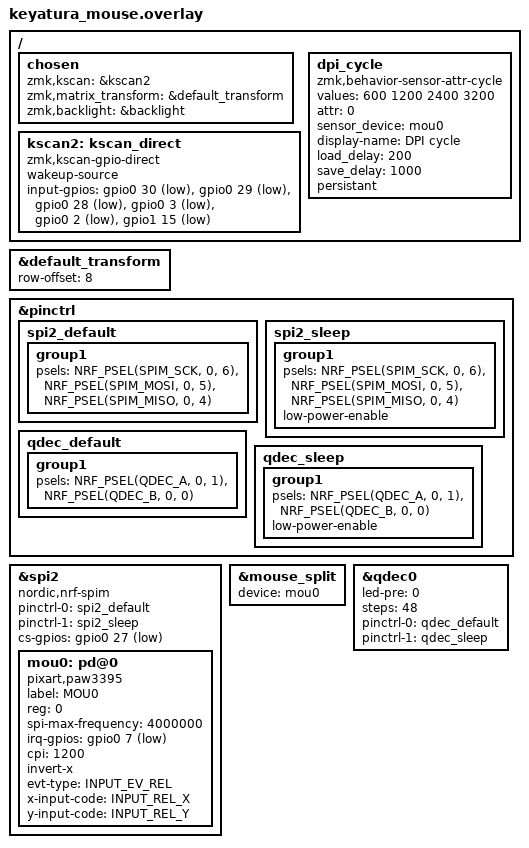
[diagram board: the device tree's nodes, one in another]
#include "keyatura.dtsi"
#include "keyatura_esb_addr.dtsi"
#include "mouse_leds.dtsi"

#define INPUT_EV_KEY 0x01               /**< Key event */
#define INPUT_EV_REL 0x02               /**< Relative coordinate event */
#define INPUT_EV_ABS 0x03               /**< Absolute coordinate event */
#define INPUT_EV_MSC 0x04               /**< Miscellaneous event */
#define INPUT_EV_VENDOR_START 0xf0      /**< Vendor specific event start */
#define INPUT_EV_VENDOR_STOP 0xff       /**< Vendor specific event stop */

#define INPUT_REL_X 0x00                /**< Relative X coordinate */
#define INPUT_REL_Y 0x01                /**< Relative Y coordinate */
#define INPUT_REL_WHEEL 0x08            /**< Relative wheel coordinate */
#define INPUT_REL_HWHEEL 0x06           /**< Relative horizontal wheel coordinate */
#define INPUT_REL_MISC 0x09             /**< Relative misc coordinate */

// &physical_layout0 {
//     kscan = <&kscan2>;
// };

/ {
	chosen {
		zmk,kscan = &kscan2;
		// zmk,physical-layout = &physical_layout0;
		zmk,matrix_transform = &default_transform;
		zmk,backlight = &backlight;
	};
	
	kscan2: kscan_direct {
		compatible = "zmk,kscan-gpio-direct";
		wakeup-source;
		input-gpios
		= <&gpio0 30 (GPIO_ACTIVE_LOW | GPIO_PULL_UP)>
		, <&gpio0 29 (GPIO_ACTIVE_LOW | GPIO_PULL_UP)>
		, <&gpio0 28 (GPIO_ACTIVE_LOW | GPIO_PULL_UP)>
		, <&gpio0 3 (GPIO_ACTIVE_LOW | GPIO_PULL_UP)>
		, <&gpio0 2 (GPIO_ACTIVE_LOW | GPIO_PULL_UP)>
		, <&gpio1 15 (GPIO_ACTIVE_LOW | GPIO_PULL_UP)>
		;
	};
};

&default_transform {
	row-offset = <8>;
};

&pinctrl {
	spi2_default: spi2_default {
		group1 {
			psels = <NRF_PSEL(SPIM_SCK, 0, 6)>,
			<NRF_PSEL(SPIM_MOSI, 0, 5)>,
			<NRF_PSEL(SPIM_MISO, 0, 4)>;
		};
	};
	spi2_sleep: spi2_sleep {
		group1 {
			psels = <NRF_PSEL(SPIM_SCK, 0, 6)>,
			<NRF_PSEL(SPIM_MOSI, 0, 5)>,
			<NRF_PSEL(SPIM_MISO, 0, 4)>;
			low-power-enable;
		};
	};
};

#include <zephyr/dt-bindings/input/input-event-codes.h>

&spi2 {
	compatible = "nordic,nrf-spim";
	status = "okay";
	pinctrl-0 = <&spi2_default>;
	pinctrl-1 = <&spi2_sleep>;
	pinctrl-names = "default", "sleep";
	cs-gpios = <&gpio0 27 GPIO_ACTIVE_LOW>;
	
	mou0: pd@0 {
		compatible = "pixart,paw3395";
		status = "okay";
		label = "MOU0";
		reg = <0>;
		spi-max-frequency = <4000000>;
		
		// paw3395 driver parameters
		irq-gpios = <&gpio0 7 (GPIO_ACTIVE_LOW | GPIO_PULL_UP)>;
		cpi = <1200>;
		// swap-xy; /* optional */
		invert-x; /* optional */
		// invert-y; /* optional */
		evt-type = <INPUT_EV_REL>;
		x-input-code = <INPUT_REL_X>;
		y-input-code = <INPUT_REL_Y>;
	};
};

&mouse_split {
	device = <&mou0>;
};

/ {
	/delete-node/ m_encoder;
};

&pinctrl {
	qdec_default: qdec_default {
		group1 {
			psels = <NRF_PSEL(QDEC_A, 0, 1)>,
			<NRF_PSEL(QDEC_B, 0, 0)>;
			// bias-pull-up;
		};
	};
	
	
	// need second set of pins defined if deep sleep is enabled
	qdec_sleep: qdec_sleep {
		group1 {
			psels = <NRF_PSEL(QDEC_A, 0, 1)>,
			<NRF_PSEL(QDEC_B, 0, 0)>;
			// bias-pull-up; // TODO: find out if this makes sense with low-power-enable
			low-power-enable;
		};
	};
};

// Set up the QDEC hardware based driver and give it the same label as the deleted node.
m_encoder: &qdec0 {
	status = "okay";
	led-pre = <0>;
	steps = <48>;
	pinctrl-0 = <&qdec_default>;
	pinctrl-1 = <&qdec_sleep>;
	pinctrl-names = "default", "sleep";
};

/ {
	dpi_cycle: dpi_cycle {
		compatible = "zmk,behavior-sensor-attr-cycle";
		#binding-cells = <1>;
		values = < 600 1200 2400 3200 >;
		attr = <0>;
		sensor_device = <&mou0>;
		display-name = "DPI cycle";
		load_delay = <200>;
		save_delay = <1000>;
		persistant;
	};
};
